# GD32F20x_CL register map
File version: 1.0
CPU: CM3 r2p1, little endian, no MPU, no FPU, 4 interrupt priority bits
Registers are 32-bit, read-write, reset 0x0 unless marked. A register's access mark holds for its fields unless they carry their own. Offsets are from the block's base; [hi:lo] are bit positions; {n}, {i} and the like mark numbered series.

## RCU — Reset and clock unit
Base 0x40021000
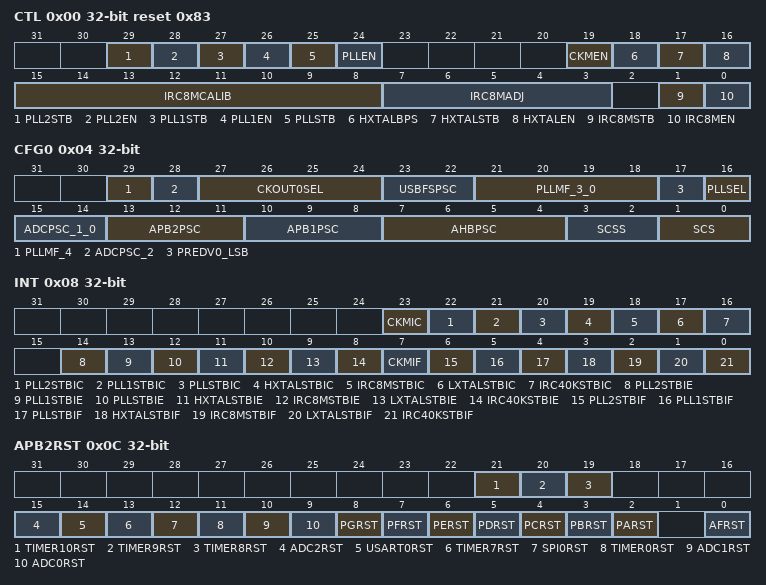
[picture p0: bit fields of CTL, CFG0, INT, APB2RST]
0x00 CTL access per field reset 0x83 — Control register
  [29] PLL2STB ro — PLL2 Clock Stabilization Flag
  [28] PLL2EN rw — PLL2 enable
  [27] PLL1STB ro — PLL1 Clock Stabilization Flag
  [26] PLL1EN rw — PLL1 enable
  [25] PLLSTB ro — PLL Clock Stabilization Flag
  [24] PLLEN rw — PLL enable
  [19] CKMEN rw — HXTAL Clock Monitor Enable
  [18] HXTALBPS rw — External crystal oscillator (HXTAL) clock bypass mode enable
  [17] HXTALSTB ro — External crystal oscillator (HXTAL) clock stabilization flag
  [16] HXTALEN rw — External High Speed oscillator Enable
  [15:8] IRC8MCALIB ro — Internal 8MHz RC Oscillator calibration value register
  [7:3] IRC8MADJ rw — Internal 8MHz RC Oscillator clock trim adjust value
  [1] IRC8MSTB ro — IRC8M Internal 8MHz RC Oscillator stabilization Flag
  [0] IRC8MEN rw — Internal 8MHz RC oscillator Enable
0x04 CFG0 access per field — Clock configuration register 0 (RCU_CFG0)
  [29] PLLMF_4 rw — Bit 4 of PLLMF
  [28] ADCPSC_2 rw — Bit 2 of ADCPSC
  [27:24] CKOUT0SEL rw — CKOUT0 Clock Source Selection
  [23:22] USBFSPSC rw — USBFS clock prescaler selection
  [21:18] PLLMF_3_0 rw — The PLL clock multiplication factor
  [17] PREDV0_LSB rw — The LSB of PREDV0 division factor
  [16] PLLSEL rw — PLL Clock Source Selection
  [15:14] ADCPSC_1_0 rw — ADC clock prescaler selection
  [13:11] APB2PSC rw — APB2 prescaler selection
  [10:8] APB1PSC rw — APB1 prescaler selection
  [7:4] AHBPSC rw — AHB prescaler selection
  [3:2] SCSS ro — System clock switch status
  [1:0] SCS rw — System clock switch
0x08 INT access per field — Clock interrupt register (RCU_INT)
  [23] CKMIC wo — HXTAL Clock Stuck Interrupt Clear
  [22] PLL2STBIC wo — PLL2 stabilization Interrupt Clear
  [21] PLL1STBIC wo — PLL1 stabilization Interrupt Clear
  [20] PLLSTBIC wo — PLL stabilization Interrupt Clear
  [19] HXTALSTBIC wo — HXTAL Stabilization Interrupt Clear
  [18] IRC8MSTBIC wo — IRC8M Stabilization Interrupt Clear
  [17] LXTALSTBIC wo — LXTAL Stabilization Interrupt Clear
  [16] IRC40KSTBIC wo — IRC40K Stabilization Interrupt Clear
  [14] PLL2STBIE rw — PLL2 Stabilization Interrupt Enable
  [13] PLL1STBIE rw — PLL1 Stabilization Interrupt Enable
  [12] PLLSTBIE rw — PLL Stabilization Interrupt Enable
  [11] HXTALSTBIE rw — HXTAL Stabilization Interrupt Enable
  [10] IRC8MSTBIE rw — IRC8M Stabilization Interrupt Enable
  [9] LXTALSTBIE rw — LXTAL Stabilization Interrupt Enable
  [8] IRC40KSTBIE rw — IRC40K Stabilization interrupt enable
  [7] CKMIF ro — HXTAL Clock Stuck Interrupt Flag
  [6] PLL2STBIF ro — PLL2 stabilization interrupt flag
  [5] PLL1STBIF ro — PLL1 stabilization interrupt flag
  [4] PLLSTBIF ro — PLL stabilization interrupt flag
  [3] HXTALSTBIF ro — HXTAL stabilization interrupt flag
  [2] IRC8MSTBIF ro — IRC8M stabilization interrupt flag
  [1] LXTALSTBIF ro — LXTAL stabilization interrupt flag
  [0] IRC40KSTBIF ro — IRC40K stabilization interrupt flag
0x0C APB2RST — APB2 reset register (RCU_APB2RST)
  [21] TIMER10RST — Timer 10 reset
  [20] TIMER9RST — Timer 9 reset
  [19] TIMER8RST — Timer 8 reset
  [15] ADC2RST — ADC2 reset
  [14] USART0RST — USART0 Reset
  [13] TIMER7RST — Timer 7 reset
  [12] SPI0RST — SPI0 reset
  [11] TIMER0RST — Timer 0 reset
  [10] ADC1RST — ADC1 reset
  [9] ADC0RST — ADC0 reset
  [8] PGRST — GPIO port G reset
  [7] PFRST — GPIO portF reset
  [6] PERST — GPIO port E reset
  [5] PDRST — GPIO port D reset
  [4] PCRST — GPIO port C reset
  [3] PBRST — GPIO port B reset
  [2] PARST — GPIO port A reset
  [0] AFRST — Alternate function I/O reset
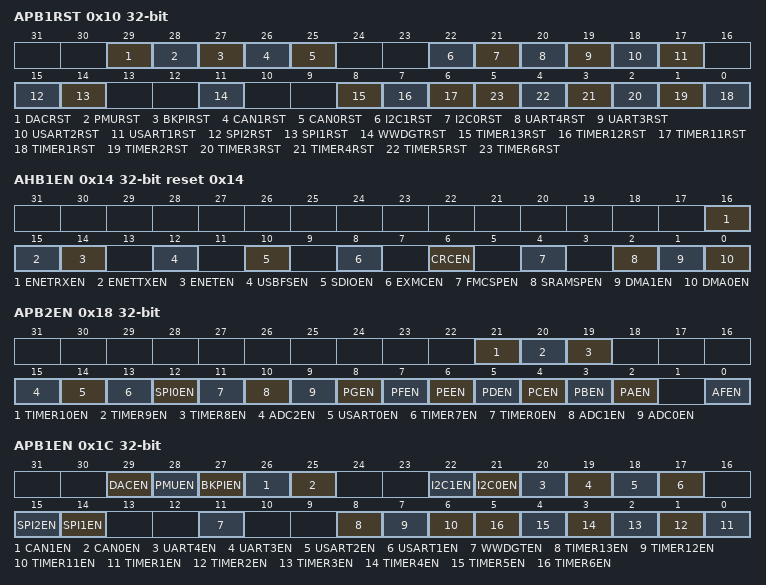
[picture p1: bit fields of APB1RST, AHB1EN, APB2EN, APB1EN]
0x10 APB1RST — APB1 reset register (RCU_APB1RST)
  [29] DACRST — DAC reset
  [28] PMURST — Power control reset
  [27] BKPIRST — Backup interface reset
  [26] CAN1RST — CAN1 reset
  [25] CAN0RST — CAN0 reset
  [22] I2C1RST — I2C1 reset
  [21] I2C0RST — I2C0 reset
  [20] UART4RST — UART4 reset
  [19] UART3RST — UART3 reset
  [18] USART2RST — USART2 reset
  [17] USART1RST — USART1 reset
  [15] SPI2RST — SPI2 reset
  [14] SPI1RST — SPI1 reset
  [11] WWDGTRST — Window watchdog timer reset
  [8] TIMER13RST — TIMER13 timer reset
  [7] TIMER12RST — TIMER12 timer reset
  [6] TIMER11RST — TIMER11 timer reset
  [n-1] TIMER{n}RST (n=1..6) — TIMER{n} timer reset
0x14 AHB1EN reset 0x14 — AHB1 enable register
  [16] ENETRXEN — Ethernet RX clock enable
  [15] ENETTXEN — Ethernet TX clock enable
  [14] ENETEN — Ethernet clock enable
  [12] USBFSEN — USBFS clock enable
  [10] SDIOEN — SDIO clock enable
  [8] EXMCEN — EXMC clock enable
  [6] CRCEN — CRC clock enable
  [4] FMCSPEN — FMC clock enable when sleep mode
  [2] SRAMSPEN — SRAM interface clock enable when sleep mode
  [1] DMA1EN — DMA1 clock enable
  [0] DMA0EN — DMA0 clock enable
0x18 APB2EN — APB2 clock enable register (RCU_APB2EN)
  [21] TIMER10EN — TIMER10 clock enable
  [20] TIMER9EN — TIMER9 clock enable
  [19] TIMER8EN — TIMER8 clock enable
  [15] ADC2EN — ADC2 clock enable
  [14] USART0EN — USART0 clock enable
  [13] TIMER7EN — TIMER7 clock enable
  [12] SPI0EN — SPI0 clock enable
  [11] TIMER0EN — TIMER0 clock enable
  [10] ADC1EN — ADC1 clock enable
  [9] ADC0EN — ADC0 clock enable
  [8] PGEN — GPIO port G clock enable
  [7] PFEN — GPIO port F clock enable
  [6] PEEN — GPIO port E clock enable
  [5] PDEN — GPIO port D clock enable
  [4] PCEN — GPIO port C clock enable
  [3] PBEN — GPIO port B clock enable
  [2] PAEN — GPIO port A clock enable
  [0] AFEN — Alternate function IO clock enable
0x1C APB1EN — APB1 clock enable register (RCU_APB1EN)
  [29] DACEN — DAC clock enable
  [28] PMUEN — Power control clock enable
  [27] BKPIEN — Backup interface clock enable
  [26] CAN1EN — CAN1 clock enable
  [25] CAN0EN — CAN0 clock enable
  [22] I2C1EN — I2C1 clock enable
  [21] I2C0EN — I2C0 clock enable
  [20] UART4EN — UART4 clock enable
  [19] UART3EN — UART3 clock enable
  [18] USART2EN — USART2 clock enable
  [17] USART1EN — USART1 clock enable
  [15] SPI2EN — SPI2 clock enable
  [14] SPI1EN — SPI1 clock enable
  [11] WWDGTEN — Window watchdog timer clock enable
  [8] TIMER13EN — TIMER13 timer clock enable
  [7] TIMER12EN — TIMER12 timer clock enable
  [6] TIMER11EN — TIMER11 timer clock enable
  [n-1] TIMER{n}EN (n=1..6) — TIMER{n} timer clock enable
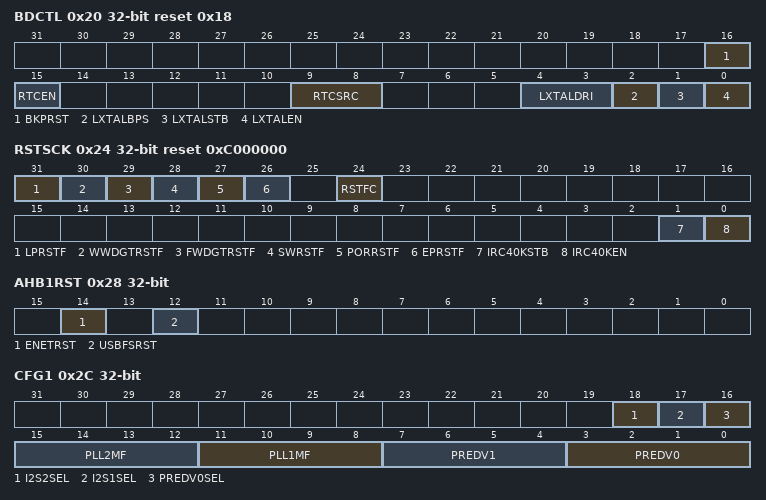
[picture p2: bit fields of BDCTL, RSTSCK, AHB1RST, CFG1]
0x20 BDCTL access per field reset 0x18 — Backup domain control register (RCU_BDCTL)
  [16] BKPRST rw — Backup domain reset
  [15] RTCEN rw — RTC clock enable
  [9:8] RTCSRC rw — RTC clock entry selection
  [4:3] LXTALDRI rw — LXTAL drive capability
  [2] LXTALBPS rw — LXTAL bypass mode enable
  [1] LXTALSTB ro — External low-speed oscillator stabilization
  [0] LXTALEN rw — LXTAL enable
0x24 RSTSCK access per field reset 0xC000000 — Reset source /clock register (RCU_RSTSCK)
  [31] LPRSTF ro — Low-power reset flag
  [30] WWDGTRSTF ro — Window watchdog timer reset flag
  [29] FWDGTRSTF ro — Free Watchdog timer reset flag
  [28] SWRSTF ro — Software reset flag
  [27] PORRSTF ro — Power reset flag
  [26] EPRSTF ro — External PIN reset flag
  [24] RSTFC rw — Reset flag clear
  [1] IRC40KSTB ro — IRC40K stabilization
  [0] IRC40KEN rw — IRC40K enable
0x28 AHB1RST — AHB1 reset register
  [14] ENETRST — ENET reset
  [12] USBFSRST — USBFS reset
0x2C CFG1 — Clock Configuration register 1
  [18] I2S2SEL — I2S2 Clock Source Selection
  [17] I2S1SEL — I2S1 Clock Source Selection
  [16] PREDV0SEL — PREDV0 input Clock Source Selection
  [15:12] PLL2MF — The PLL2 clock multiplication factor
  [11:8] PLL1MF — The PLL1 clock multiplication factor
  [7:4] PREDV1 — PREDV1 division factor
  [3:0] PREDV0 — PREDV0 division factor
0x34 DSV — Deep sleep mode Voltage register
  [2:0] DSLPVS — Deep-sleep mode voltage select
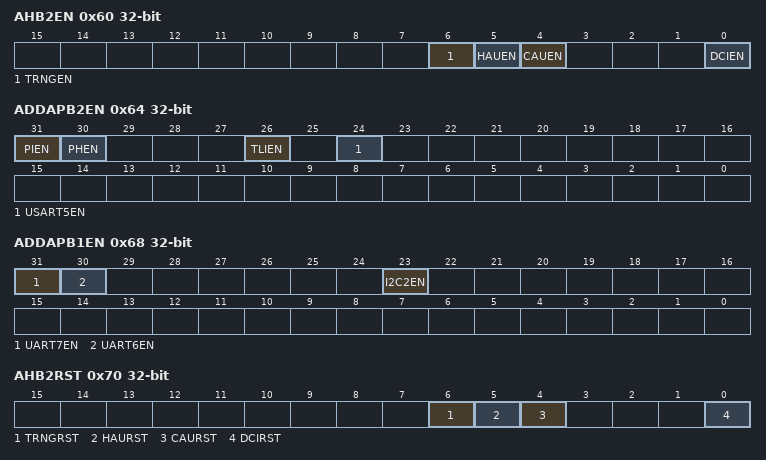
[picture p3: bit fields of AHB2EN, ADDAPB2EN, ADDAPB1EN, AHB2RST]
0x60 AHB2EN — AHB2 enable register
  [6] TRNGEN — TRNG clock enable
  [5] HAUEN — HAU clock enable
  [4] CAUEN — CAU clock enable
  [0] DCIEN — DCI clock enable
0x64 ADDAPB2EN — APB2 additional enable register
  [31] PIEN — GPIO port I clock enable
  [30] PHEN — GPIO port H clock enable
  [26] TLIEN — TLI clock enable
  [24] USART5EN — USART5 clock enable
0x68 ADDAPB1EN — APB1 additional enable register
  [31] UART7EN — UART7 clock enable
  [30] UART6EN — UART6 clock enable
  [23] I2C2EN — I2C2 clock enable
0x70 AHB2RST — AHB2 reset register
  [6] TRNGRST — TRNG reset
  [5] HAURST — HAU reset
  [4] CAURST — CAU reset
  [0] DCIRST — DCI reset
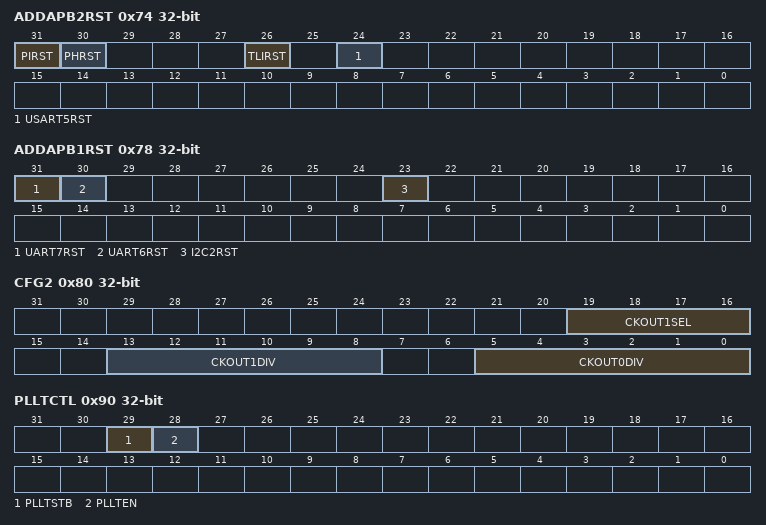
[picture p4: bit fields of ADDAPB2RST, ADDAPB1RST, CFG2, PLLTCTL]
0x74 ADDAPB2RST — APB2 additional enable register
  [31] PIRST — GPIO port I reset
  [30] PHRST — GPIO port H reset
  [26] TLIRST — TLI reset
  [24] USART5RST — USART5 reset
0x78 ADDAPB1RST — APB1 additional enable register
  [31] UART7RST — UART7 reset
  [30] UART6RST — UART6 reset
  [23] I2C2RST — I2C2 reset
0x80 CFG2 — configuration register 2
  [19:16] CKOUT1SEL — CK_OUT1 clock source selection
  [13:8] CKOUT1DIV — the CK_OUT1 divider
  [5:0] CKOUT0DIV — the CK_OUT0 divider
0x90 PLLTCTL access per field — PLLT control register
  [29] PLLTSTB ro — PLLTclock stabilization flag
  [28] PLLTEN rw — PLLT enable
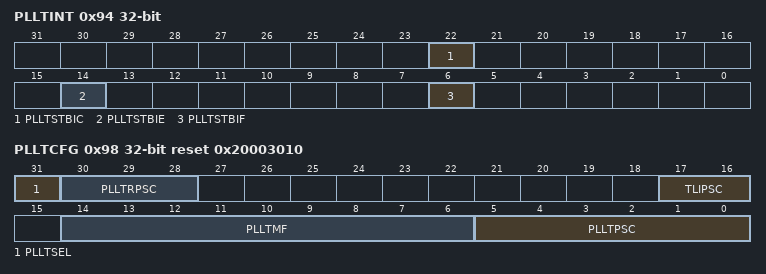
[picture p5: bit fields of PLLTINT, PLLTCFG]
0x94 PLLTINT access per field — PLLT interrupt register
  [22] PLLTSTBIC rw — PLLT stabilization Interrupt clear
  [14] PLLTSTBIE rw — PLLT stabilization Interrupt Enable
  [6] PLLTSTBIF ro — PLLT stabilization interrupt flag
0x98 PLLTCFG reset 0x20003010 — PLLT configuration register
  [31] PLLTSEL — PLLT clock source select
  [30:28] PLLTRPSC — PLLTR prescaler selection
  [17:16] TLIPSC — TLI prescaler selection
  [14:6] PLLTMF — PLLT multiply factor for VCO
  [5:0] PLLTPSC — PLLT prescaler selection
